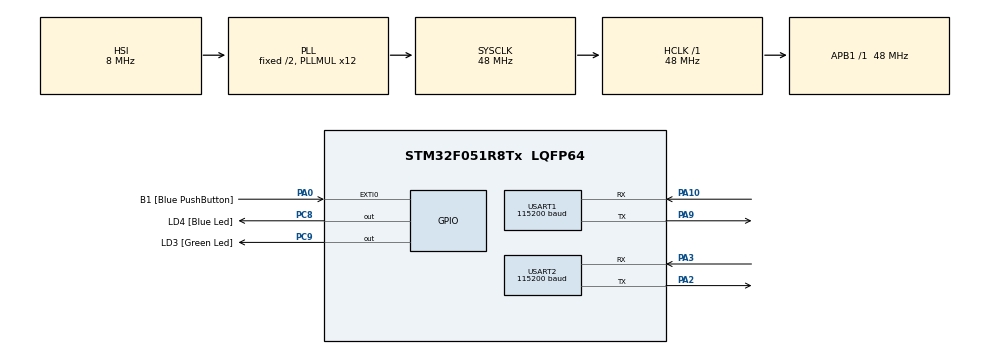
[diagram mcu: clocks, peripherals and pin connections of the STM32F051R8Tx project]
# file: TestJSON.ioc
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Mcu.Family=STM32F0
PA10.Mode=Asynchronous
PC9.GPIO_Label=LD3 [Green Led]
USART1.BaudRate=115200
PA14.GPIO_Label=SWCLK
PA0.GPIO_Label=B1 [Blue PushButton]
PC8.Signal=GPIO_Output
NVIC.USART2_IRQn=true\:0\:0\:false\:false\:true\:true\:true
USART2.BaudRate=115200
RCC.SYSCLKSource=RCC_SYSCLKSOURCE_PLLCLK
ProjectManager.StackSize=0x800
PC8.GPIO_Label=LD4 [Blue Led]
USART1.VirtualMode-Asynchronous=VM_ASYNC
PA3.Mode=Asynchronous
PA13.Signal=SYS_SWDIO
PA9.Mode=Asynchronous
TIM1.Prescaler=48
ProjectManager.TargetToolchain=STM32CubeIDE
RCC.HCLKFreq_Value=48000000
PA9.Signal=USART1_TX
RCC.AHBFreq_Value=48000000
board=STM32F0DISCOVERY
USART2.VirtualMode-Asynchronous=VM_ASYNC
RCC.PLLMUL=RCC_PLL_MUL12
VP_TIM2_VS_ClockSourceINT.Mode=Internal
PA14.Mode=Serial_Wire
PA0.GPIO_ModeDefaultEXTI=GPIO_MODE_EVT_RISING
NVIC.TIM2_IRQn=true\:0\:0\:false\:false\:true\:true\:true
TIM2.Period=999
PA13.Mode=Serial_Wire
Mcu.Name=STM32F051R8Tx
VP_TIM1_VS_ClockSourceINT.Mode=Internal
PA2.Signal=USART2_TX
PA13.GPIO_Label=SWDIO
PA0.Signal=GPXTI0
NVIC.TIM1_CC_IRQn=true\:0\:0\:false\:false\:true\:true\:true
RCC.SYSCLKFreq_VALUE=48000000
Mcu.Package=LQFP64
TIM2.Prescaler=48
PA10.Signal=USART1_RX
PA14.Signal=SYS_SWCLK
ProjectManager.HeapSize=0x800
RCC.APB1TimFreq_Value=48000000
PA2.Mode=Asynchronous
TIM1.Period=999
PC9.Signal=GPIO_Output
NVIC.USART1_IRQn=true\:0\:0\:false\:false\:true\:true\:true
RCC.APB1Freq_Value=48000000
NVIC.TIM1_BRK_UP_TRG_COM_IRQn=true\:0\:0\:false\:false\:true\:true\:true
PA3.Signal=USART2_RX

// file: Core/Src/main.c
/* USER CODE BEGIN Header */
/**
  ******************************************************************************
  * @file           : main.c
  * @brief          : Main program body
  ******************************************************************************
  * @attention
  *
  * <h2><center>&copy; Copyright (c) 2023 STMicroelectronics.
  * All rights reserved.</center></h2>
  *
  * This software component is licensed by ST under BSD 3-Clause license,
  * the "License"; You may not use this file except in compliance with the
  * License. You may obtain a copy of the License at:
  *                        opensource.org/licenses/BSD-3-Clause
  *
  ******************************************************************************
  */
/* USER CODE END Header */
#include "main.h"

/* USER CODE BEGIN Includes */
#include "cJSON.h"
#include "mb.h"
#include <string.h>
/* USER CODE END Includes */

TIM_HandleTypeDef htim1;
TIM_HandleTypeDef htim2;

UART_HandleTypeDef huart1;
UART_HandleTypeDef huart2;

void SystemClock_Config(void);
static void MX_GPIO_Init(void);
static void MX_USART1_UART_Init(void);
static void MX_USART2_UART_Init(void);
static void MX_TIM1_Init(void);
static void MX_TIM2_Init(void);

/* USER CODE BEGIN 0 */
eModbus modbus_no1;
eModbus modbus_no2;

uint8_t data;
/* USER CODE END 0 */

int main(void)
{

  /* MCU Configuration--------------------------------------------------------*/

  /* Reset of all peripherals, Initializes the Flash interface and the Systick. */
  HAL_Init();

  /* Configure the system clock */
  SystemClock_Config();

  /* Initialize all configured peripherals */
  MX_GPIO_Init();
  MX_USART1_UART_Init();
  MX_USART2_UART_Init();
  MX_TIM1_Init();
  MX_TIM2_Init();
  /* USER CODE BEGIN 2 */
  eMBInit(&modbus_no1,MB_RTU,1,0,115200,MB_PAR_NONE);
  eMBEnable(&modbus_no1);
  eMBInit(&modbus_no2,MB_RTU,1,1,115200,MB_PAR_NONE);
  eMBEnable(&modbus_no2);
//  HAL_UART_Receive_IT(&huart1, &data,1);
  /* USER CODE END 2 */

  /* Infinite loop */
  /* USER CODE BEGIN WHILE */
  while (1)
  {
//	  HAL_UART_Transmit(&huart1,(uint8_t*) "Hello world\r\n",strlen("Hello world\r\n"), 1000);
//	  HAL_Delay(1000);
	  eMBPoll(&modbus_no1);
	  eMBPoll(&modbus_no2);
    /* USER CODE END WHILE */

  }
}

void SystemClock_Config(void)
{
  RCC_OscInitTypeDef RCC_OscInitStruct = {0};
  RCC_ClkInitTypeDef RCC_ClkInitStruct = {0};
  RCC_PeriphCLKInitTypeDef PeriphClkInit = {0};

  /** Initializes the RCC Oscillators according to the specified parameters
  * in the RCC_OscInitTypeDef structure.
  */
  RCC_OscInitStruct.OscillatorType = RCC_OSCILLATORTYPE_HSI;
  RCC_OscInitStruct.HSIState = RCC_HSI_ON;
  RCC_OscInitStruct.HSICalibrationValue = RCC_HSICALIBRATION_DEFAULT;
  RCC_OscInitStruct.PLL.PLLState = RCC_PLL_ON;
  RCC_OscInitStruct.PLL.PLLSource = RCC_PLLSOURCE_HSI;
  RCC_OscInitStruct.PLL.PLLMUL = RCC_PLL_MUL12;
  RCC_OscInitStruct.PLL.PREDIV = RCC_PREDIV_DIV1;
  if (HAL_RCC_OscConfig(&RCC_OscInitStruct) != HAL_OK)
  {
    Error_Handler();
  }
  /** Initializes the CPU, AHB and APB buses clocks
  */
  RCC_ClkInitStruct.ClockType = RCC_CLOCKTYPE_HCLK|RCC_CLOCKTYPE_SYSCLK
                              |RCC_CLOCKTYPE_PCLK1;
  RCC_ClkInitStruct.SYSCLKSource = RCC_SYSCLKSOURCE_PLLCLK;
  RCC_ClkInitStruct.AHBCLKDivider = RCC_SYSCLK_DIV1;
  RCC_ClkInitStruct.APB1CLKDivider = RCC_HCLK_DIV1;

  if (HAL_RCC_ClockConfig(&RCC_ClkInitStruct, FLASH_LATENCY_1) != HAL_OK)
  {
    Error_Handler();
  }
  PeriphClkInit.PeriphClockSelection = RCC_PERIPHCLK_USART1;
  PeriphClkInit.Usart1ClockSelection = RCC_USART1CLKSOURCE_PCLK1;
  if (HAL_RCCEx_PeriphCLKConfig(&PeriphClkInit) != HAL_OK)
  {
    Error_Handler();
  }
}

static void MX_TIM1_Init(void)
{

  TIM_ClockConfigTypeDef sClockSourceConfig = {0};
  TIM_MasterConfigTypeDef sMasterConfig = {0};

  htim1.Instance = TIM1;
  htim1.Init.Prescaler = 48;
  htim1.Init.CounterMode = TIM_COUNTERMODE_UP;
  htim1.Init.Period = 99999;
  htim1.Init.ClockDivision = TIM_CLOCKDIVISION_DIV1;
  htim1.Init.RepetitionCounter = 0;
  htim1.Init.AutoReloadPreload = TIM_AUTORELOAD_PRELOAD_DISABLE;
  if (HAL_TIM_Base_Init(&htim1) != HAL_OK)
  {
    Error_Handler();
  }
  sClockSourceConfig.ClockSource = TIM_CLOCKSOURCE_INTERNAL;
  if (HAL_TIM_ConfigClockSource(&htim1, &sClockSourceConfig) != HAL_OK)
  {
    Error_Handler();
  }
  sMasterConfig.MasterOutputTrigger = TIM_TRGO_RESET;
  sMasterConfig.MasterSlaveMode = TIM_MASTERSLAVEMODE_DISABLE;
  if (HAL_TIMEx_MasterConfigSynchronization(&htim1, &sMasterConfig) != HAL_OK)
  {
    Error_Handler();
  }

}

static void MX_TIM2_Init(void)
{

  TIM_ClockConfigTypeDef sClockSourceConfig = {0};
  TIM_MasterConfigTypeDef sMasterConfig = {0};

  htim2.Instance = TIM2;
  htim2.Init.Prescaler = 48;
  htim2.Init.CounterMode = TIM_COUNTERMODE_UP;
  htim2.Init.Period = 999;
  htim2.Init.ClockDivision = TIM_CLOCKDIVISION_DIV1;
  htim2.Init.AutoReloadPreload = TIM_AUTORELOAD_PRELOAD_DISABLE;
  if (HAL_TIM_Base_Init(&htim2) != HAL_OK)
  {
    Error_Handler();
  }
  sClockSourceConfig.ClockSource = TIM_CLOCKSOURCE_INTERNAL;
  if (HAL_TIM_ConfigClockSource(&htim2, &sClockSourceConfig) != HAL_OK)
  {
    Error_Handler();
  }
  sMasterConfig.MasterOutputTrigger = TIM_TRGO_RESET;
  sMasterConfig.MasterSlaveMode = TIM_MASTERSLAVEMODE_DISABLE;
  if (HAL_TIMEx_MasterConfigSynchronization(&htim2, &sMasterConfig) != HAL_OK)
  {
    Error_Handler();
  }

}

static void MX_USART1_UART_Init(void)
{

  huart1.Instance = USART1;
  huart1.Init.BaudRate = 115200;
  huart1.Init.WordLength = UART_WORDLENGTH_8B;
  huart1.Init.StopBits = UART_STOPBITS_1;
  huart1.Init.Parity = UART_PARITY_NONE;
  huart1.Init.Mode = UART_MODE_TX_RX;
  huart1.Init.HwFlowCtl = UART_HWCONTROL_NONE;
  huart1.Init.OverSampling = UART_OVERSAMPLING_16;
  huart1.Init.OneBitSampling = UART_ONE_BIT_SAMPLE_DISABLE;
  huart1.AdvancedInit.AdvFeatureInit = UART_ADVFEATURE_NO_INIT;
  if (HAL_UART_Init(&huart1) != HAL_OK)
  {
    Error_Handler();
  }

}

static void MX_USART2_UART_Init(void)
{

  huart2.Instance = USART2;
  huart2.Init.BaudRate = 115200;
  huart2.Init.WordLength = UART_WORDLENGTH_8B;
  huart2.Init.StopBits = UART_STOPBITS_1;
  huart2.Init.Parity = UART_PARITY_NONE;
  huart2.Init.Mode = UART_MODE_TX_RX;
  huart2.Init.HwFlowCtl = UART_HWCONTROL_NONE;
  huart2.Init.OverSampling = UART_OVERSAMPLING_16;
  huart2.Init.OneBitSampling = UART_ONE_BIT_SAMPLE_DISABLE;
  huart2.AdvancedInit.AdvFeatureInit = UART_ADVFEATURE_NO_INIT;
  if (HAL_UART_Init(&huart2) != HAL_OK)
  {
    Error_Handler();
  }

}

static void MX_GPIO_Init(void)
{
  GPIO_InitTypeDef GPIO_InitStruct = {0};

  /* GPIO Ports Clock Enable */
  __HAL_RCC_GPIOA_CLK_ENABLE();
  __HAL_RCC_GPIOC_CLK_ENABLE();

  /*Configure GPIO pin Output Level */
  HAL_GPIO_WritePin(GPIOC, LD4_Pin|LD3_Pin, GPIO_PIN_RESET);

  /*Configure GPIO pin : B1_Pin */
  GPIO_InitStruct.Pin = B1_Pin;
  GPIO_InitStruct.Mode = GPIO_MODE_EVT_RISING;
  GPIO_InitStruct.Pull = GPIO_NOPULL;
  HAL_GPIO_Init(B1_GPIO_Port, &GPIO_InitStruct);

  /*Configure GPIO pins : LD4_Pin LD3_Pin */
  GPIO_InitStruct.Pin = LD4_Pin|LD3_Pin;
  GPIO_InitStruct.Mode = GPIO_MODE_OUTPUT_PP;
  GPIO_InitStruct.Pull = GPIO_NOPULL;
  GPIO_InitStruct.Speed = GPIO_SPEED_FREQ_LOW;
  HAL_GPIO_Init(GPIOC, &GPIO_InitStruct);

}

void Error_Handler(void)
{
  __disable_irq();
  while (1)
  {
  }
}

/************************ (C) COPYRIGHT STMicroelectronics *****END OF FILE****/
